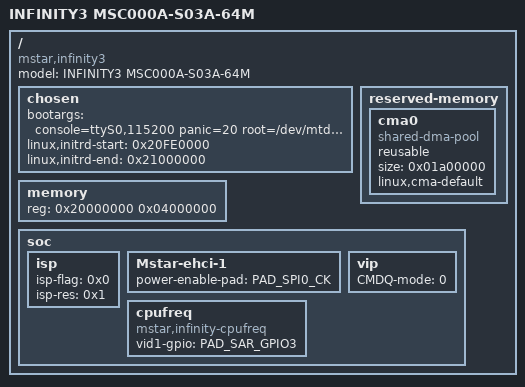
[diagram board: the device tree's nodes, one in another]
/*
 * Copyright (c) 2014 MundoReader S.L.
 * Author: Matthias Brugger <matthias.bgg@gmail.com>
 *
 * This program is free software; you can redistribute it and/or modify
 * it under the terms of the GNU General Public License as published by
 * the Free Software Foundation; either version 2 of the License, or
 * (at your option) any later version.
 *
 * This program is distributed in the hope that it will be useful,
 * but WITHOUT ANY WARRANTY; without even the implied warranty of
 * MERCHANTABILITY or FITNESS FOR A PARTICULAR PURPOSE.  See the
 * GNU General Public License for more details.
 */

/dts-v1/;
#include "infinity3.dtsi"

/ {
    model = "INFINITY3 MSC000A-S03A-64M";
    compatible = "mstar,infinity3";


    chosen {
        bootargs = "console=ttyS0,115200 panic=20 root=/dev/mtdblock3 rootfstype=squashfs init=/init";
        linux,initrd-start = <0x20FE0000>;
        linux,initrd-end =   <0x21000000>;
    };

    memory {
        reg = <0x20000000 0x04000000>;
    };

/*!!IMPORTANT!! The reserved memory must be 1MB aligned*/
    reserved-memory {
        #address-cells = <1>;
        #size-cells = <1>;
        ranges;

/*
        miu_bist_mem: miu_bist_mem@23F00000 {
            reg = <0x23F00000 0x00100000>;
            no-map ;
            status = "okay";
        };
*/

        cma0 {
            compatible = "shared-dma-pool";
            reusable;
            size = <0x01a00000>;
            linux,cma-default;
        };
    };

    soc {
        isp: isp {
            //clk-pad = <PAD_SPI0_CK>; //be compatible with the previous QFN, so it must reserved 4 pins for SPI0 pads
            isp-flag = <0x0>; //Disable DNR and ROT
            isp-res = <0x1>; //max image size 2M
        };
        Mstar-ehci-1 {
            power-enable-pad = <PAD_SPI0_CK>;
        };
        vip: vip {
            CMDQ-mode = <0>;
        };
        cpufreq {
            compatible = "mstar,infinity-cpufreq";
            vid1-gpio = <PAD_SAR_GPIO3>;
        };
    };
};
